VERSION ""

NS_ :

BS_:

BU_: HU

BO_ 285 VCU_HUDisp_2: 8 CGW
 SG_ VCU_MotActlSpdValid : 55|1@0+ (1,0) [0|1] "" TBox,HU

BO_ 400 iBCM_BCMSts: 8 CGW
 SG_ iBCM_AntitheftSts : 7|2@0+ (1,0) [0|3] "" TBox,HU
 SG_ iBCM_PwrMod : 5|2@0+ (1,0) [0|3] "" TBox,HU,PAS
 SG_ iBCM_HoodSts : 1|1@0+ (1,0) [0|1] "" HU
 SG_ iBCM_VhclDoorLckSts : 15|1@0+ (1,0) [0|1] "" TBox,HU
 SG_ iBCM_FL_DoorAjarSts : 14|1@0+ (1,0) [0|1] "" TBox,HU
 SG_ iBCM_FR_DoorAjarSts : 13|1@0+ (1,0) [0|1] "" TBox,HU
 SG_ iBCM_RL_DoorAjarSts : 12|1@0+ (1,0) [0|1] "" TBox,HU
 SG_ iBCM_RR_DoorAjarSts : 11|1@0+ (1,0) [0|1] "" TBox,HU
 SG_ iBCM_PBDLckSts : 23|1@0+ (1,0) [0|1] "" HU
 SG_ iBCM_PosnLiSts : 22|1@0+ (1,0) [0|1] "" HU
 SG_ iBCM_HiBeamSts : 21|1@0+ (1,0) [0|1] "" HU
 SG_ iBCM_LoBeamSts : 20|1@0+ (1,0) [0|1] "" HU
 SG_ iBCM_ReFogLiSts : 18|1@0+ (1,0) [0|1] "" HU
 SG_ iBCM_FrntFogLiSts : 17|1@0+ (1,0) [0|1] "" HU
 SG_ iBCM_TurnLiSts : 31|2@0+ (1,0) [0|3] "" TBox,HU
 SG_ iBCM_BrkLiSwch : 27|1@0+ (1,0) [0|1] "" HU
 SG_ iBCM_DrvrPresenceSgnl : 26|2@0+ (1,0) [0|3] "" HU
 SG_ iBCM_FolwMeHomeSts : 24|1@0+ (1,0) [0|1] "" HU
 SG_ iBCM_HomeTiDlySetg : 39|8@0+ (1,0) [0|60] "s" HU

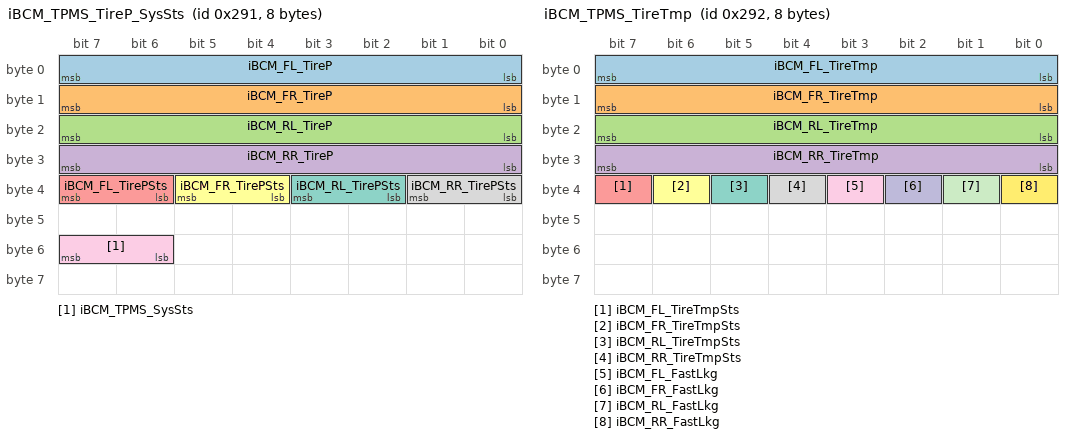
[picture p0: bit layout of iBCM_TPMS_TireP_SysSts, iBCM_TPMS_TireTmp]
BO_ 657 iBCM_TPMS_TireP_SysSts: 8 CGW
 SG_ iBCM_FL_TireP : 7|8@0+ (1.373,0) [0|348.742] "kpa" TBox,HU
 SG_ iBCM_FR_TireP : 15|8@0+ (1.373,0) [0|348.742] "kpa" TBox,HU
 SG_ iBCM_RL_TireP : 23|8@0+ (1.373,0) [0|348.742] "kpa" TBox,HU
 SG_ iBCM_RR_TireP : 31|8@0+ (1.373,0) [0|348.742] "kpa" TBox,HU
 SG_ iBCM_FL_TirePSts : 39|2@0+ (1,0) [0|3] "" TBox,HU
 SG_ iBCM_FR_TirePSts : 37|2@0+ (1,0) [0|3] "" TBox,HU
 SG_ iBCM_RL_TirePSts : 35|2@0+ (1,0) [0|3] "" TBox,HU
 SG_ iBCM_RR_TirePSts : 33|2@0+ (1,0) [0|3] "" TBox,HU
 SG_ iBCM_TPMS_SysSts : 55|2@0+ (1,0) [0|3] "" HU

BO_ 658 iBCM_TPMS_TireTmp: 8 CGW
 SG_ iBCM_FL_TireTmp : 7|8@0+ (1,-50) [-50|204] "℃" TBox,HU
 SG_ iBCM_FR_TireTmp : 15|8@0+ (1,-50) [-50|204] "℃" TBox,HU
 SG_ iBCM_RL_TireTmp : 23|8@0+ (1,-50) [-50|204] "℃" TBox,HU
 SG_ iBCM_RR_TireTmp : 31|8@0+ (1,-50) [-50|204] "℃" TBox,HU
 SG_ iBCM_FL_TireTmpSts : 39|1@0+ (1,0) [0|1] "" TBox,HU
 SG_ iBCM_FR_TireTmpSts : 38|1@0+ (1,0) [0|1] "" TBox,HU
 SG_ iBCM_RL_TireTmpSts : 37|1@0+ (1,0) [0|1] "" TBox,HU
 SG_ iBCM_RR_TireTmpSts : 36|1@0+ (1,0) [0|1] "" TBox,HU
 SG_ iBCM_FL_FastLkg : 35|1@0+ (1,0) [0|1] "" TBox,HU
 SG_ iBCM_FR_FastLkg : 34|1@0+ (1,0) [0|1] "" TBox,HU
 SG_ iBCM_RL_FastLkg : 33|1@0+ (1,0) [0|1] "" TBox,HU
 SG_ iBCM_RR_FastLkg : 32|1@0+ (1,0) [0|1] "" TBox,HU

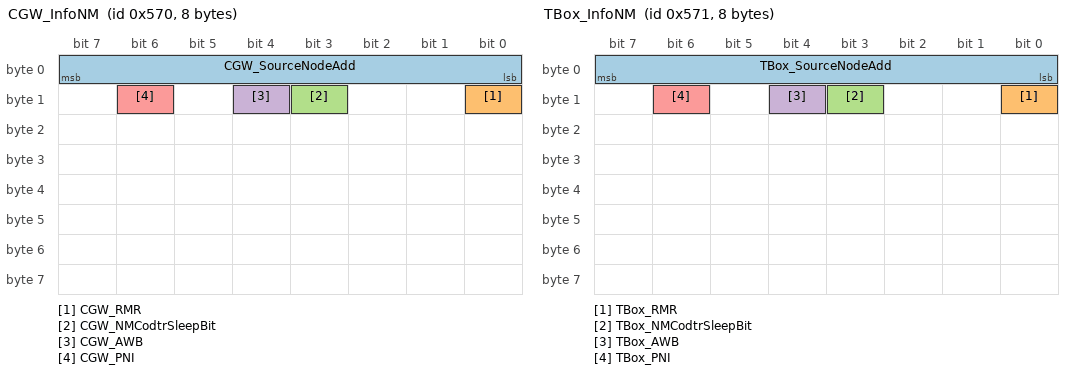
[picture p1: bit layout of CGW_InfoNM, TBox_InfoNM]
BO_ 1392 CGW_InfoNM: 8 CGW
 SG_ CGW_SourceNodeAdd : 7|8@0+ (1,0) [112|112] "" TBox,HU,AMP
 SG_ CGW_RMR : 8|1@0+ (1,0) [0|1] "" TBox,HU,AMP
 SG_ CGW_NMCodtrSleepBit : 11|1@0+ (1,0) [0|1] "" TBox,HU,AMP
 SG_ CGW_AWB : 12|1@0+ (1,0) [0|1] "" TBox,HU,AMP
 SG_ CGW_PNI : 14|1@0+ (1,0) [0|1] "" TBox,HU,AMP

BO_ 1393 TBox_InfoNM: 8 TBox
 SG_ TBox_SourceNodeAdd : 7|8@0+ (1,0) [113|113] "" HU,AMP,CGW
 SG_ TBox_RMR : 8|1@0+ (1,0) [0|1] "" HU,AMP,CGW
 SG_ TBox_NMCodtrSleepBit : 11|1@0+ (1,0) [0|1] "" HU,AMP,CGW
 SG_ TBox_AWB : 12|1@0+ (1,0) [0|1] "" HU,AMP,CGW
 SG_ TBox_PNI : 14|1@0+ (1,0) [0|1] "" HU,AMP,CGW

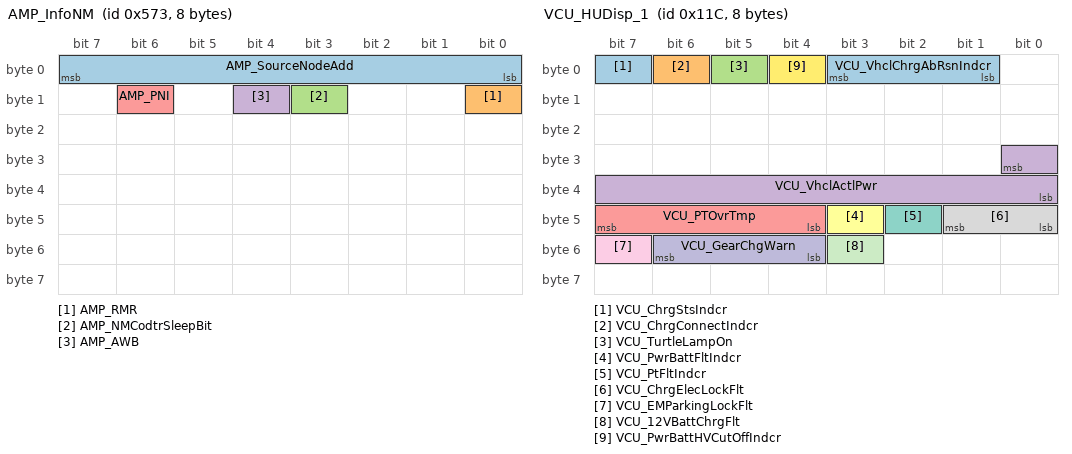
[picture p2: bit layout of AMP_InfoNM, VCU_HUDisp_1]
BO_ 1395 AMP_InfoNM: 8 AMP
 SG_ AMP_SourceNodeAdd : 7|8@0+ (1,0) [115|115] "" TBox,HU,CGW
 SG_ AMP_RMR : 8|1@0+ (1,0) [0|1] "" TBox,HU,CGW
 SG_ AMP_NMCodtrSleepBit : 11|1@0+ (1,0) [0|1] "" TBox,HU,CGW
 SG_ AMP_AWB : 12|1@0+ (1,0) [0|1] "" TBox,HU,CGW
 SG_ AMP_PNI : 14|1@0+ (1,0) [0|1] "" TBox,HU,CGW

BO_ 284 VCU_HUDisp_1: 8 CGW
 SG_ VCU_ChrgStsIndcr : 7|1@0+ (1,0) [0|1] "" TBox,HU,AMP
 SG_ VCU_ChrgConnectIndcr : 6|1@0+ (1,0) [0|1] "" TBox,HU
 SG_ VCU_TurtleLampOn : 5|1@0+ (1,0) [0|1] "" HU
 SG_ VCU_VhclActlPwr : 24|9@0+ (1,-200) [-200|300] "kw" HU
 SG_ VCU_PTOvrTmp : 47|4@0+ (1,0) [0|15] "" HU
 SG_ VCU_PwrBattFltIndcr : 43|1@0+ (1,0) [0|1] "" HU
 SG_ VCU_PtFltIndcr : 42|1@0+ (1,0) [0|1] "" HU
 SG_ VCU_ChrgElecLockFlt : 41|2@0+ (1,0) [0|3] "" HU
 SG_ VCU_EMParkingLockFlt : 55|1@0+ (1,0) [0|1] "" HU
 SG_ VCU_GearChgWarn : 54|3@0+ (1,0) [0|7] "" HU
 SG_ VCU_12VBattChrgFlt : 51|1@0+ (1,0) [0|1] "" HU
 SG_ VCU_PwrBattHVCutOffIndcr : 4|1@0+ (1,0) [0|1] "" HU
 SG_ VCU_VhclChrgAbRsnIndcr : 3|3@0+ (1,0) [0|7] "" HU

BO_ 369 CGW_ChassisToInfo: 8 CGW
 SG_ ESP_VhclSpd : 7|13@0+ (0.05625,0) [0|300] "km/h" TBox,HU,AMP,PAS
 SG_ ESP_VhclSpd_Vld : 10|1@0+ (1,0) [0|1] "" TBox,HU,AMP,PAS
 SG_ ESP_OFFLamp : 9|1@0+ (1,0) [0|1] "" HU
 SG_ ESP_Err : 8|1@0+ (1,0) [0|1] "" HU
 SG_ ESP_ABS_Err : 23|1@0+ (1,0) [0|1] "" HU
 SG_ ESP_EBD_Err : 22|1@0+ (1,0) [0|1] "" HU
 SG_ ESP_HMI_WarnOn : 21|1@0+ (1,0) [0|1] "" HU
 SG_ ESP_Actv : 20|1@0+ (1,0) [0|1] "" HU
 SG_ ESP_EPB_WarnMsg : 19|4@0+ (1,0) [0|15] "" HU
 SG_ ESP_EPB_FltLamp : 31|2@0+ (1,0) [0|3] "" TBox,HU,PAS
 SG_ ESP_EPB_FctLamp : 29|2@0+ (1,0) [0|3] "" HU
 SG_ ESP_AVH_Avl : 24|1@0+ (1,0) [0|1] "" HU
 SG_ ESP_AVH_Actv : 39|1@0+ (1,0) [0|1] "" HU
 SG_ ESP_HDC_Avl : 38|1@0+ (1,0) [0|1] "" HU
 SG_ ESP_HDC_Sts : 37|2@0+ (1,0) [0|3] "" HU
 SG_ iB_HU_WarnOn : 32|1@0+ (1,0) [0|1] "" HU
 SG_ EPS_Sts : 47|2@0+ (1,0) [0|3] "" HU

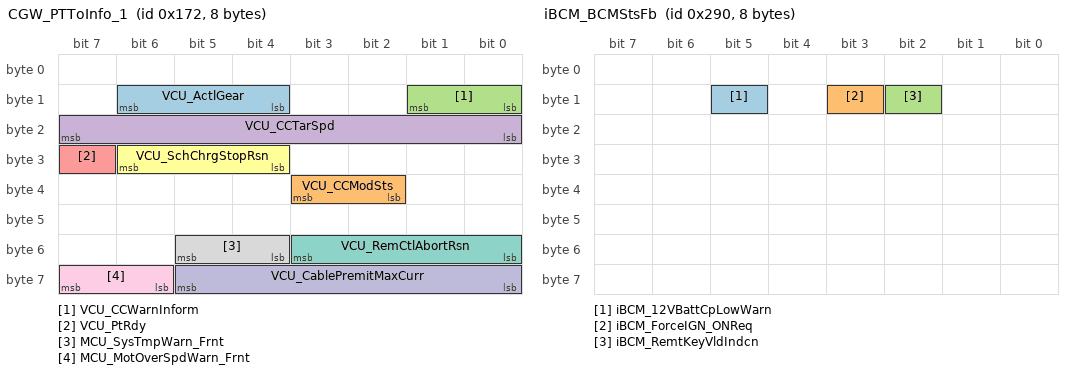
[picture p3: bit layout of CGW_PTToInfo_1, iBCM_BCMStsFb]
BO_ 370 CGW_PTToInfo_1: 8 CGW
 SG_ VCU_ActlGear : 14|3@0+ (1,0) [0|7] "" TBox,HU,AMP,PAS
 SG_ VCU_CCModSts : 35|2@0+ (1,0) [0|3] "" HU
 SG_ VCU_CCWarnInform : 9|2@0+ (1,0) [0|3] "" HU
 SG_ VCU_CCTarSpd : 23|8@0+ (1,0) [0|150] "km/h" HU
 SG_ VCU_PtRdy : 31|1@0+ (1,0) [0|1] "" TBox,HU,AMP,PAS
 SG_ VCU_SchChrgStopRsn : 30|3@0+ (1,0) [0|7] "" TBox,HU
 SG_ VCU_RemCtlAbortRsn : 51|4@0+ (1,0) [0|15] "" HU
 SG_ MCU_SysTmpWarn_Frnt : 53|2@0+ (1,0) [0|3] "" HU
 SG_ MCU_MotOverSpdWarn_Frnt : 63|2@0+ (1,0) [0|3] "" HU
 SG_ VCU_CablePremitMaxCurr : 61|6@0+ (1,0) [8|32] "A" HU

BO_ 656 iBCM_BCMStsFb: 8 CGW
 SG_ iBCM_12VBattCpLowWarn : 13|1@0+ (1,0) [0|1] "" HU
 SG_ iBCM_ForceIGN_ONReq : 11|1@0+ (1,0) [0|1] "" HU
 SG_ iBCM_RemtKeyVldIndcn : 10|1@0+ (1,0) [0|1] "" HU

BO_ 880 TBox_Order: 8 TBox
 SG_ TBox_CurChrgnMod : 6|2@0+ (1,0) [0|3] "" HU,CGW
 SG_ TBox_E_CallSts : 47|2@0+ (1,0) [0|3] "" HU,CGW

CM_ SG_ 1395 AMP_SourceNodeAdd "Source Node Address
原节点地址";
CM_ SG_ 1395 AMP_RMR "Repeat message request
重复报文请求";
CM_ SG_ 1395 AMP_NMCodtrSleepBit "NM Coordinator Sleep Bit
网络管理协调睡眠指示位";
CM_ SG_ 1395 AMP_AWB "Active wakeup bit
主动唤醒指示位";
CM_ SG_ 1395 AMP_PNI "Partial netwark information bit 
局部网络指示位";
CM_ SG_ 880 TBox_CurChrgnMod "Current Charging Mode
当前充电模式信号";
CM_ SG_ 880 TBox_E_CallSts "TBox_EmergencyCallStatus
一键呼叫通话状态";
CM_ SG_ 1393 TBox_SourceNodeAdd "Source Node Address
原节点地址";
CM_ SG_ 1393 TBox_RMR "Repeat message request
重复报文请求";
CM_ SG_ 1393 TBox_NMCodtrSleepBit "NM Coordinator Sleep Bit
网络管理协调睡眠指示位";
CM_ SG_ 1393 TBox_AWB "Active wakeup bit
主动唤醒指示位";
CM_ SG_ 1393 TBox_PNI "Partial netwark information bit 
局部网络指示位";
CM_ SG_ 1392 CGW_SourceNodeAdd "Source Node Address
原节点地址";
CM_ SG_ 1392 CGW_RMR "Repeat message request
重复报文请求";
CM_ SG_ 1392 CGW_NMCodtrSleepBit "NM Coordinator Sleep Bit
网络管理协调睡眠指示位";
CM_ SG_ 1392 CGW_AWB "Active wakeup bit
主动唤醒指示位";
CM_ SG_ 1392 CGW_PNI "Partial netwark information bit 
局部网络指示位";
CM_ SG_ 284 VCU_ChrgStsIndcr "Charge status indicator
充电状态指示";
CM_ SG_ 284 VCU_ChrgConnectIndcr "Charge connect indicator
充电链接指示";
CM_ SG_ 284 VCU_TurtleLampOn "TurtleLampOn
（乌龟灯）驱动功率受限指示灯";
CM_ SG_ 284 VCU_VhclActlPwr "Vehicle actual power
车辆实际功率";
CM_ SG_ 284 VCU_PTOvrTmp "Powertrain over temperature
动力系统过温";
CM_ SG_ 284 VCU_PwrBattFltIndcr "Power battery fault indicator
动力电池故障指示";
CM_ SG_ 284 VCU_PtFltIndcr "Powertrain fault indicator
动力系统故障指示";
CM_ SG_ 284 VCU_ChrgElecLockFlt "Charging electrical lock fault
充电电子锁故障";
CM_ SG_ 284 VCU_EMParkingLockFlt "EM parking lock fault
电机驻车锁故障";
CM_ SG_ 284 VCU_GearChgWarn "Gear Change Warning
换档条件不满足";
CM_ SG_ 284 VCU_12VBattChrgFlt "Battery(12V) Charging Fault
12V蓄电池充电故障指示";
CM_ SG_ 284 VCU_PwrBattHVCutOffIndcr "Power Battery High Voltage Cut Off  Indicator
动力电池高压切断指示";
CM_ SG_ 284 VCU_VhclChrgAbRsnIndcr "Vehicle Charge Abnormal  Reason Indicator
车辆充电异常原因指示";
CM_ SG_ 285 VCU_MotActlSpdValid "Motor Actual speed validity 
电机实际转速有效";
CM_ SG_ 370 VCU_ActlGear "Actual gear";
CM_ SG_ 370 VCU_CCModSts "Cruise control mode status
巡航控制模式状态";
CM_ SG_ 370 VCU_CCWarnInform "Cruise control warning information
巡航控制报警信息";
CM_ SG_ 370 VCU_CCTarSpd "Cruise control target speed
巡航目标车速";
CM_ SG_ 370 VCU_PtRdy "Powertrain have ready
动力系统准备就绪";
CM_ SG_ 370 VCU_SchChrgStopRsn "Schedule charging stop reason
预约充电停止充电的原因";
CM_ SG_ 370 VCU_RemCtlAbortRsn "Remote control abort reason
远程控制失败的原因";
CM_ SG_ 370 MCU_SysTmpWarn_Frnt "Systerm temperature waring
电机系统温度报警";
CM_ SG_ 370 MCU_MotOverSpdWarn_Frnt "Motor over speed warnig
电机超速报警";
CM_ SG_ 370 VCU_CablePremitMaxCurr "AC Charging cable premit max current
交流充电线缆允许的最大电流";
CM_ SG_ 369 ESP_VhclSpd "Vehicle speed out";
CM_ SG_ 369 ESP_VhclSpd_Vld "Vehicle speed out status";
CM_ SG_ 369 ESP_OFFLamp "ESP is diabled by PATA(PATALamp)
（ESP_OFF Switch)";
CM_ SG_ 369 ESP_Err "ESP_Fault: VDC/TCS is switched off due to detected failure";
CM_ SG_ 369 ESP_ABS_Err "ABS_Fault: ESP system has detected a failure which does not allow a reliable ABS regulation and is therefore switched off";
CM_ SG_ 369 ESP_EBD_Err "EBD_Fault: ESP system has detected a heavy fault, which does not even allow a reliable electronic brake distribution and is therefore completely shut down";
CM_ SG_ 369 ESP_HMI_WarnOn "Warning lamp of ESPhev
(iBooster fault indicator)";
CM_ SG_ 369 ESP_Actv "Info lamp  Indication that VDC/TCS(brake torque control) system currently performs a brake intervention";
CM_ SG_ 369 ESP_EPB_WarnMsg "Additional warning message to inform the driver how to do the next step.";
CM_ SG_ 369 ESP_EPB_FltLamp "EPB_FailureLamp";
CM_ SG_ 369 ESP_EPB_FctLamp "EPB_FunctionLamp";
CM_ SG_ 369 ESP_AVH_Avl "HMI Responsible,CAN get degrateAVH statement from DSW(Didgnostic Software) and send out";
CM_ SG_ 369 ESP_AVH_Actv "Indicates AVH in active or not ";
CM_ SG_ 369 ESP_HDC_Avl "HMI Responsible,CAN get degrate HDC statement from DSW and send out";
CM_ SG_ 369 ESP_HDC_Sts "HDC Status(Off/On, not active braking/On, active braking)
HDC state is used for light the dashboard lamp for Off, Standby, active: 
Off, the lamp is Off;
Standby, the lamp is On;
Active,the lamp is blinking.";
CM_ SG_ 369 iB_HU_WarnOn "Warning lamp of iBooster";
CM_ SG_ 369 EPS_Sts "EPS Status
EPS系统状态信号";
CM_ SG_ 657 iBCM_FL_TireP "TireLeftFrontPressure
左前轮胎压压力";
CM_ SG_ 657 iBCM_FR_TireP "TireRightFrontPressure
右前轮胎压压力";
CM_ SG_ 657 iBCM_RL_TireP "TireLeftRearPressure
左后轮胎压压力";
CM_ SG_ 657 iBCM_RR_TireP "TireRightRearPressure
右后轮胎压压力";
CM_ SG_ 657 iBCM_FL_TirePSts "TireLeftFrontPressureStatus
左前轮胎压状态";
CM_ SG_ 657 iBCM_FR_TirePSts "TireRightFrontPressureStatus
右前轮胎压状态";
CM_ SG_ 657 iBCM_RL_TirePSts "TireLeftRearPressureStatus
左后轮胎压状态";
CM_ SG_ 657 iBCM_RR_TirePSts "TireRightRearPressureStatus
右后轮胎压状态";
CM_ SG_ 657 iBCM_TPMS_SysSts "TPMSSystemStatus
TPMS系统状态";
CM_ SG_ 658 iBCM_FL_TireTmp "TireLeftFrontTemperature
左前轮胎温";
CM_ SG_ 658 iBCM_FR_TireTmp "TireRightFrontTemperature
右前轮胎温";
CM_ SG_ 658 iBCM_RL_TireTmp "TireLeftRearTemperature
左后轮胎温";
CM_ SG_ 658 iBCM_RR_TireTmp "TireRightRearTemperature
右后轮胎温";
CM_ SG_ 658 iBCM_FL_TireTmpSts "TireLeftFrontTemperatureStatus
左前轮轮胎温状态";
CM_ SG_ 658 iBCM_FR_TireTmpSts "TireRightFrontTemperatureStatus
右前轮轮胎温状态";
CM_ SG_ 658 iBCM_RL_TireTmpSts "TireLeftRearTemperatureStatus
左后轮轮胎温状态";
CM_ SG_ 658 iBCM_RR_TireTmpSts "TireRightRearTemperatureStatus
右后轮轮胎温状态";
CM_ SG_ 658 iBCM_FL_FastLkg "Tire Front Left FastLeakage
左前轮快速漏气(预留)";
CM_ SG_ 658 iBCM_FR_FastLkg "Tire Front Right FastLeakage
右前轮快速漏气(预留)";
CM_ SG_ 658 iBCM_RL_FastLkg "Tire Rear Left FastLeakage
左后轮快速漏气(预留)";
CM_ SG_ 658 iBCM_RR_FastLkg "Tire Rear Right Fast Leakage
右后轮快速漏气(预留)";
CM_ SG_ 656 iBCM_12VBattCpLowWarn "Battery(12V) Capacity Low Warning
12V电池低电量信号";
CM_ SG_ 656 iBCM_ForceIGN_ONReq "Force IGN ON Request
（座椅传感器失效时）请求用户确认是否强制IGN ON";
CM_ SG_ 656 iBCM_RemtKeyVldIndcn "Valid Indication of the Remote Key 
遥控钥匙有效指示位";
CM_ SG_ 400 iBCM_AntitheftSts "Vehicle Antitheft Status
防盗报警状态";
CM_ SG_ 400 iBCM_PwrMod "Power Mode
系统电源";
CM_ SG_ 400 iBCM_HoodSts "Hood Status
前舱盖开关";
CM_ SG_ 400 iBCM_VhclDoorLckSts "Vehicle Door Lock Status
整车门锁状态";
CM_ SG_ 400 iBCM_FL_DoorAjarSts "Driver Door Ajar Status
驾驶侧门开关状态";
CM_ SG_ 400 iBCM_FR_DoorAjarSts "Passenger Door Ajar Status
副驾驶侧门开关状态";
CM_ SG_ 400 iBCM_RL_DoorAjarSts "Rear Left Door Ajar Status
左后门开关状态";
CM_ SG_ 400 iBCM_RR_DoorAjarSts "Rear Right Door Ajar Status
右后门开关状态";
CM_ SG_ 400 iBCM_PBDLckSts "PBD Lock Status
电动背门锁状态";
CM_ SG_ 400 iBCM_PosnLiSts "Position Light Status
位置灯状态";
CM_ SG_ 400 iBCM_HiBeamSts "High Beam Status
远光灯状态";
CM_ SG_ 400 iBCM_LoBeamSts "Low Beam status
近光灯状态";
CM_ SG_ 400 iBCM_ReFogLiSts "Rear Fog Lamp Status 
后雾灯状态";
CM_ SG_ 400 iBCM_FrntFogLiSts "Front Fog Lamp Status 
前雾灯状态";
CM_ SG_ 400 iBCM_TurnLiSts "Turn Lamp Status and Hazard Warning Lamp Status
 转向灯/危险警告状态";
CM_ SG_ 400 iBCM_BrkLiSwch "Brake Light Switch
制动灯开关信号";
CM_ SG_ 400 iBCM_DrvrPresenceSgnl "Driver Presence Signal
座椅传感器信号";
CM_ SG_ 400 iBCM_FolwMeHomeSts "Follow Me Home Function Status
伴我回家功能（启闭）状态";
CM_ SG_ 400 iBCM_HomeTiDlySetg "The setting of Follow Me Home TimeDely  in iBCM  Memory
iBCM内伴我回家灯延迟时间设定";

BA_DEF_ BO_  "NmMessage" ENUM "No","Yes";
BA_DEF_ BO_  "GenMsgSendType" ENUM  "Cycle","NoSendType","IfActive";
BA_DEF_ BO_  "GenMsgCycleTime" INT 0 0;
BA_DEF_ SG_  "GenSigSendType" ENUM  "Cycle","OnChange","OnWrite","IfActive","OnChangeWithRepetition","OnWriteWithRepetition","IfActiveWithRepetition";
BA_DEF_ SG_  "GenSigStartValue" INT 0 0;
BA_DEF_ BO_  "GenMsgCycleTimeFast" INT 0 0;
BA_DEF_ BO_  "GenMsgNrOfRepetition" INT 0 0;
BA_DEF_ BO_  "VFrameFormat" ENUM  "StandardCAN","ExtendedCAN","reserved","reserved","reserved","reserved","reserved","reserved","reserved","reserved","reserved","reserved","reserved","reserved","StandardCAN_FD","ExtendedCAN_FD";

BA_DEF_DEF_  "NmMessage" "No";
BA_DEF_DEF_  "GenMsgSendType" "Cycle";
BA_DEF_DEF_  "GenMsgCycleTime" 0;
BA_DEF_DEF_  "GenSigSendType" "Cycle";
BA_DEF_DEF_  "GenSigStartValue" 0;
BA_DEF_DEF_  "GenMsgCycleTimeFast" 0;
BA_DEF_DEF_  "GenMsgNrOfRepetition" 0;
BA_DEF_DEF_  "VFrameFormat" "StandardCAN";
BA_ "GenMsgCycleTime" BO_ 400 100;
BA_ "GenMsgCycleTime" BO_ 657 200;
BA_ "GenSigStartValue" SG_ 657 iBCM_FL_TireP 255;
BA_ "GenSigStartValue" SG_ 657 iBCM_FR_TireP 255;
BA_ "GenSigStartValue" SG_ 657 iBCM_RL_TireP 255;
BA_ "GenSigStartValue" SG_ 657 iBCM_RR_TireP 255;
BA_ "GenMsgCycleTime" BO_ 658 200;
BA_ "GenSigStartValue" SG_ 658 iBCM_FL_TireTmp 255;
BA_ "GenSigStartValue" SG_ 658 iBCM_FR_TireTmp 255;
BA_ "GenSigStartValue" SG_ 658 iBCM_RL_TireTmp 255;
BA_ "GenSigStartValue" SG_ 658 iBCM_RR_TireTmp 255;
BA_ "NmMessage" BO_ 1392 1;
BA_ "GenMsgCycleTime" BO_ 1392 500;
BA_ "GenMsgCycleTimeFast" BO_ 1392 10;
BA_ "GenMsgNrOfRepetition" BO_ 1392 5;
BA_ "GenSigSendType" SG_ 1392 CGW_SourceNodeAdd 6;
BA_ "GenSigStartValue" SG_ 1392 CGW_SourceNodeAdd 112;
BA_ "GenSigSendType" SG_ 1392 CGW_RMR 6;
BA_ "GenSigSendType" SG_ 1392 CGW_NMCodtrSleepBit 6;
BA_ "GenSigSendType" SG_ 1392 CGW_AWB 6;
BA_ "GenSigSendType" SG_ 1392 CGW_PNI 6;
BA_ "NmMessage" BO_ 1393 1;
BA_ "GenMsgCycleTime" BO_ 1393 500;
BA_ "GenMsgCycleTimeFast" BO_ 1393 10;
BA_ "GenMsgNrOfRepetition" BO_ 1393 5;
BA_ "GenSigSendType" SG_ 1393 TBox_SourceNodeAdd 6;
BA_ "GenSigStartValue" SG_ 1393 TBox_SourceNodeAdd 113;
BA_ "GenSigSendType" SG_ 1393 TBox_RMR 6;
BA_ "GenSigSendType" SG_ 1393 TBox_NMCodtrSleepBit 6;
BA_ "GenSigSendType" SG_ 1393 TBox_AWB 6;
BA_ "GenSigSendType" SG_ 1393 TBox_PNI 6;
BA_ "NmMessage" BO_ 1395 1;
BA_ "GenMsgCycleTime" BO_ 1395 500;
BA_ "GenMsgCycleTimeFast" BO_ 1395 10;
BA_ "GenMsgNrOfRepetition" BO_ 1395 5;
BA_ "GenSigSendType" SG_ 1395 AMP_SourceNodeAdd 6;
BA_ "GenSigStartValue" SG_ 1395 AMP_SourceNodeAdd 115;
BA_ "GenSigSendType" SG_ 1395 AMP_RMR 6;
BA_ "GenSigSendType" SG_ 1395 AMP_NMCodtrSleepBit 6;
BA_ "GenSigSendType" SG_ 1395 AMP_AWB 6;
BA_ "GenSigSendType" SG_ 1395 AMP_PNI 6;
BA_ "GenMsgCycleTime" BO_ 284 100;
BA_ "GenSigStartValue" SG_ 284 VCU_VhclActlPwr 200;
BA_ "GenMsgCycleTime" BO_ 369 20;
BA_ "GenSigStartValue" SG_ 369 ESP_Err 1;
BA_ "GenSigStartValue" SG_ 369 ESP_ABS_Err 1;
BA_ "GenSigStartValue" SG_ 369 ESP_EBD_Err 1;
BA_ "GenMsgCycleTime" BO_ 370 50;
BA_ "GenSigStartValue" SG_ 370 VCU_CablePremitMaxCurr 8;
BA_ "GenMsgCycleTime" BO_ 656 100;
BA_ "GenMsgCycleTime" BO_ 880 50;
VAL_ 1395 AMP_RMR 1 "Rpt Msg state req" 0 "Rpt Msg state not req" ;
VAL_ 1395 AMP_NMCodtrSleepBit 1 "Synch Shutdwn Req by codtr" 0 "Synch Shutdwn NotReq by codtr" ;
VAL_ 1395 AMP_AWB 1 "Active wakeup" 0 "Passive wakeup" ;
VAL_ 1395 AMP_PNI 1 "Contain PNI" 0 "Contain no PNI" ;
VAL_ 880 TBox_CurChrgnMod 3 "Reserved" 2 "Reserved" 1 "Remote Charging Mode" 0 "Normal Charging Mode" ;
VAL_ 880 TBox_E_CallSts 3 "Hang up" 2 "Call connection" 1 "Dialing" 0 "No request" ;
VAL_ 1393 TBox_RMR 1 "Rpt Msg state req" 0 "Rpt Msg state not req" ;
VAL_ 1393 TBox_NMCodtrSleepBit 1 "Synch Shutdwn Req by codtr" 0 "Synch Shutdwn NotReq by codtr" ;
VAL_ 1393 TBox_AWB 1 "Active wakeup" 0 "Passive wakeup" ;
VAL_ 1393 TBox_PNI 1 "Contain PNI" 0 "Contain no PNI" ;
VAL_ 1392 CGW_RMR 1 "Rpt Msg state req" 0 "Rpt Msg state not req" ;
VAL_ 1392 CGW_NMCodtrSleepBit 1 "Synch Shutdwn Req by codtr" 0 "Synch Shutdwn NotReq by codtr" ;
VAL_ 1392 CGW_AWB 1 "Active wakeup" 0 "Passive wakeup" ;
VAL_ 1392 CGW_PNI 1 "Contain PNI" 0 "Contain no PNI" ;
VAL_ 284 VCU_ChrgStsIndcr 1 "True" 0 "False" ;
VAL_ 284 VCU_ChrgConnectIndcr 1 "True" 0 "False" ;
VAL_ 284 VCU_TurtleLampOn 1 "Lamp on" 0 "Lamp off" ;
VAL_ 284 VCU_VhclActlPwr 511 "Invalid" 510 "Invalid" 509 "Invalid" 508 "Invalid" 507 "Invalid" 506 "Invalid" 505 "Invalid" 504 "Invalid" 503 "Invalid" 502 "Invalid" 501 "Invalid" ;
VAL_ 284 VCU_PTOvrTmp 15 "Reserved" 14 "Reserved" 13 "Reserved" 12 "Reserved" 11 "Reserved" 10 "Reserved" 9 "Reserved" 8 "Reserved" 7 "Reserved" 6 "Reserved" 5 "Reserved" 4 "PTCoolant over tmp" 3 "Both Front and Rear Motor system over tmp" 2 "Rear Motor system over tmp" 1 "Front Motor system over tmp" 0 "Normal" ;
VAL_ 284 VCU_PwrBattFltIndcr 1 "True" 0 "False" ;
VAL_ 284 VCU_PtFltIndcr 1 "True" 0 "False" ;
VAL_ 284 VCU_ChrgElecLockFlt 3 "Reserved" 2 "Electrincal Lock can't Opened" 1 "Electrincal Lock can't Locked" 0 "No fault" ;
VAL_ 284 VCU_EMParkingLockFlt 1 "Fault" 0 "No fault" ;
VAL_ 284 VCU_GearChgWarn 7 "Reserved" 6 "Reserved" 5 "GSM Fault" 4 "PT fault can't change gear" 3 "Close door to shift none P" 2 "Press BrkPed to shift none P" 1 "Vehicle speed too high" 0 "No warning" ;
VAL_ 284 VCU_12VBattChrgFlt 1 "Error" 0 "No Error" ;
VAL_ 284 VCU_PwrBattHVCutOffIndcr 1 "Cut Off" 0 "No Cut Off" ;
VAL_ 284 VCU_VhclChrgAbRsnIndcr 7 "Reserved" 6 "Reserved" 5 "Reserved" 4 "Reserved" 3 "Reserved" 2 "Chrg Timeout, Please Check" 1 "Vhcl Not On P,Cannot Chrg" 0 "Normal" ;
VAL_ 285 VCU_MotActlSpdValid 1 "Validity" 0 "Invalidity" ;
VAL_ 370 VCU_ActlGear 7 "Reserved" 6 "Reserved" 5 "Reserved" 4 "Reserved" 3 "D" 2 "N" 1 "R" 0 "P" ;
VAL_ 370 VCU_CCModSts 3 "Cancel" 2 "Active" 1 "Standby" 0 "Off" ;
VAL_ 370 VCU_CCWarnInform 3 "Reserved" 2 "CC systerm fault" 1 "Condition not fulfill" 0 "No error" ;
VAL_ 370 VCU_CCTarSpd 255 "Invalid" 254 "Invalid" 253 "Invalid" 252 "Invalid" 251 "Invalid" 250 "Invalid" 249 "Invalid" 248 "Invalid" 247 "Invalid" 246 "Invalid" 245 "Invalid" 244 "Invalid" 243 "Invalid" 242 "Invalid" 241 "Invalid" 240 "Invalid" 239 "Invalid" 238 "Invalid" 237 "Invalid" 236 "Invalid" 235 "Invalid" 234 "Invalid" 233 "Invalid" 232 "Invalid" 231 "Invalid" 230 "Invalid" 229 "Invalid" 228 "Invalid" 227 "Invalid" 226 "Invalid" 225 "Invalid" 224 "Invalid" 223 "Invalid" 222 "Invalid" 221 "Invalid" 220 "Invalid" 219 "Invalid" 218 "Invalid" 217 "Invalid" 216 "Invalid" 215 "Invalid" 214 "Invalid" 213 "Invalid" 212 "Invalid" 211 "Invalid" 210 "Invalid" 209 "Invalid" 208 "Invalid" 207 "Invalid" 206 "Invalid" 205 "Invalid" 204 "Invalid" 203 "Invalid" 202 "Invalid" 201 "Invalid" 200 "Invalid" 199 "Invalid" 198 "Invalid" 197 "Invalid" 196 "Invalid" 195 "Invalid" 194 "Invalid" 193 "Invalid" 192 "Invalid" 191 "Invalid" 190 "Invalid" 189 "Invalid" 188 "Invalid" 187 "Invalid" 186 "Invalid" 185 "Invalid" 184 "Invalid" 183 "Invalid" 182 "Invalid" 181 "Invalid" 180 "Invalid" 179 "Invalid" 178 "Invalid" 177 "Invalid" 176 "Invalid" 175 "Invalid" 174 "Invalid" 173 "Invalid" 172 "Invalid" 171 "Invalid" 170 "Invalid" 169 "Invalid" 168 "Invalid" 167 "Invalid" 166 "Invalid" 165 "Invalid" 164 "Invalid" 163 "Invalid" 162 "Invalid" 161 "Invalid" 160 "Invalid" 159 "Invalid" 158 "Invalid" 157 "Invalid" 156 "Invalid" 155 "Invalid" 154 "Invalid" 153 "Invalid" 152 "Invalid" 151 "Invalid" ;
VAL_ 370 VCU_PtRdy 1 "True" 0 "False" ;
VAL_ 370 VCU_SchChrgStopRsn 7 "Reserved" 6 "Crash happened" 5 "Charging gun not plug in" 4 "220V not connect(CC but no CP)" 3 "Normal stop" 2 "PT system fault stop" 1 "Charging full stop" 0 "Default" ;
VAL_ 370 VCU_RemCtlAbortRsn 15 "Reserved" 14 "Reserved" 13 "Reserved" 12 "Reserved" 11 "Reserved" 10 "Reserved" 9 "Reserved" 8 "SOC low" 7 "Permit Max time timeout" 6 "Driver intervene Accr Ped" 5 "Driver intervene Brake Ped" 4 "Driver intervene Gear" 3 "Plug in charging gun" 2 "PT system fault" 1 "None P" 0 "Default" ;
VAL_ 370 MCU_SysTmpWarn_Frnt 3 "Coolant over tmp dreating" 2 "Motore over tmp dreating" 1 "MCU over tmp dreating" 0 "Normal" ;
VAL_ 370 MCU_MotOverSpdWarn_Frnt 3 "Reserved" 2 "Fault" 1 "Derating" 0 "Normal" ;
VAL_ 370 VCU_CablePremitMaxCurr 63 "Invalid" 62 "Invalid" 61 "Invalid" 60 "Invalid" 59 "Invalid" 58 "Invalid" 57 "Invalid" 56 "Invalid" 55 "Invalid" 54 "Invalid" 53 "Invalid" 52 "Invalid" 51 "Invalid" 50 "Invalid" 49 "Invalid" 48 "Invalid" 47 "Invalid" 46 "Invalid" 45 "Invalid" 44 "Invalid" 43 "Invalid" 42 "Invalid" 41 "Invalid" 40 "Invalid" 39 "Invalid" 38 "Invalid" 37 "Invalid" 36 "Invalid" 35 "Invalid" 34 "Invalid" 33 "Invalid" ;
VAL_ 369 ESP_VhclSpd 8191 "Invalid" ;
VAL_ 369 ESP_VhclSpd_Vld 1 "Validity" 0 "Invalidity" ;
VAL_ 369 ESP_OFFLamp 1 "Lamp On" 0 "Lamp Off" ;
VAL_ 369 ESP_Err 1 "Error" 0 "No error" ;
VAL_ 369 ESP_ABS_Err 1 "Error" 0 "No error" ;
VAL_ 369 ESP_EBD_Err 1 "Error" 0 "No error" ;
VAL_ 369 ESP_HMI_WarnOn 1 "Warning lamp requested" 0 "No request to the warning lamp" ;
VAL_ 369 ESP_Actv 1 "Active" 0 "Not active" ;
VAL_ 369 ESP_EPB_WarnMsg 15 "Reserved" 14 "Reserved" 13 "Reserved" 12 "Reserved" 11 "Reserved" 10 "Reserved" 9 "Roller Bench Mode" 8 "Contact Service to check EPB" 7 "ClampForceNotEnough ?" 6 "GradientTooHigh ?" 5 "MaintenanceModeActive" 4 "DynamicBrakingActive ?" 3 "PressBrakePedal ?" 2 "OpenEPBBySwitch ?" 1 "FastenSeatBelt ?" 0 "Off" ;
VAL_ 369 ESP_EPB_FltLamp 3 "Reserved" 2 "EPB failure lamp blinking" 1 "EPB failure lamp On" 0 "EPB failure lamp Off" ;
VAL_ 369 ESP_EPB_FctLamp 3 "Reserved" 2 "EPB function lamp blinking" 1 "EPB function lamp On" 0 "EPB function lamp Off" ;
VAL_ 369 ESP_AVH_Avl 1 "Available" 0 "Not available" ;
VAL_ 369 ESP_AVH_Actv 1 "Active" 0 "Not active" ;
VAL_ 369 ESP_HDC_Avl 1 "Available" 0 "Not available" ;
VAL_ 369 ESP_HDC_Sts 3 "Reserved" 2 "On active braking" 1 "On not active braking" 0 "OFF" ;
VAL_ 369 iB_HU_WarnOn 1 "iB Lamp Active" 0 "No iB Lamp" ;
VAL_ 369 EPS_Sts 3 "Reserved" 2 "Intermittent Error Detected" 1 "Permanent Error Detected" 0 "No Fault" ;
VAL_ 657 iBCM_FL_TireP 255 "Invalid" ;
VAL_ 657 iBCM_FR_TireP 255 "Invalid" ;
VAL_ 657 iBCM_RL_TireP 255 "Invalid" ;
VAL_ 657 iBCM_RR_TireP 255 "Invalid" ;
VAL_ 657 iBCM_FL_TirePSts 3 "Reserved" 2 "Under-pressure" 1 "Over-pressure" 0 "Normal" ;
VAL_ 657 iBCM_FR_TirePSts 3 "Reserved" 2 "Under-pressure" 1 "Over-pressure" 0 "Normal" ;
VAL_ 657 iBCM_RL_TirePSts 3 "Reserved" 2 "Under-pressure" 1 "Over-pressure" 0 "Normal" ;
VAL_ 657 iBCM_RR_TirePSts 3 "Reserved" 2 "Under-pressure" 1 "Over-pressure" 0 "Normal" ;
VAL_ 657 iBCM_TPMS_SysSts 3 "Reserved" 2 "Reserved" 1 "System is abnormal" 0 "System is ok" ;
VAL_ 658 iBCM_FL_TireTmp 255 "Invalid" ;
VAL_ 658 iBCM_FR_TireTmp 255 "Invalid" ;
VAL_ 658 iBCM_RL_TireTmp 255 "Invalid" ;
VAL_ 658 iBCM_RR_TireTmp 255 "Invalid" ;
VAL_ 658 iBCM_FL_TireTmpSts 1 "Over-temp" 0 "Normal" ;
VAL_ 658 iBCM_FR_TireTmpSts 1 "Over-temp" 0 "Normal" ;
VAL_ 658 iBCM_RL_TireTmpSts 1 "Over-temp" 0 "Normal" ;
VAL_ 658 iBCM_RR_TireTmpSts 1 "Over-temp" 0 "Normal" ;
VAL_ 658 iBCM_FL_FastLkg 1 "Fast Leakage" 0 "Not Fast Leakage" ;
VAL_ 658 iBCM_FR_FastLkg 1 "Fast Leakage" 0 "Not Fast Leakage" ;
VAL_ 658 iBCM_RL_FastLkg 1 "Fast Leakage" 0 "Not Fast Leakage" ;
VAL_ 658 iBCM_RR_FastLkg 1 "Fast Leakage" 0 "Not Fast Leakage" ;
VAL_ 656 iBCM_12VBattCpLowWarn 1 "Warning" 0 "No Warning" ;
VAL_ 656 iBCM_ForceIGN_ONReq 1 "Request" 0 "No Request" ;
VAL_ 656 iBCM_RemtKeyVldIndcn 1 "Validity" 0 "Invalidity" ;
VAL_ 400 iBCM_AntitheftSts 3 "Alarmed" 2 "Prearmed" 1 "Armed" 0 "Disarmed" ;
VAL_ 400 iBCM_PwrMod 3 "Reserved" 2 "ON" 1 "ACC" 0 "OFF" ;
VAL_ 400 iBCM_HoodSts 1 "Open" 0 "Close" ;
VAL_ 400 iBCM_VhclDoorLckSts 1 "Lock" 0 "Unlock" ;
VAL_ 400 iBCM_FL_DoorAjarSts 1 "Open" 0 "Close" ;
VAL_ 400 iBCM_FR_DoorAjarSts 1 "Open" 0 "Close" ;
VAL_ 400 iBCM_RL_DoorAjarSts 1 "Open" 0 "Close" ;
VAL_ 400 iBCM_RR_DoorAjarSts 1 "Open" 0 "Close" ;
VAL_ 400 iBCM_PBDLckSts 1 "Lock" 0 "Unlock" ;
VAL_ 400 iBCM_PosnLiSts 1 "On" 0 "Off" ;
VAL_ 400 iBCM_HiBeamSts 1 "On" 0 "Off" ;
VAL_ 400 iBCM_LoBeamSts 1 "On" 0 "Off" ;
VAL_ 400 iBCM_ReFogLiSts 1 "On" 0 "Off" ;
VAL_ 400 iBCM_FrntFogLiSts 1 "On" 0 "Off" ;
VAL_ 400 iBCM_TurnLiSts 3 "Hazard warning on" 2 "Left turn lamp on" 1 "Right turn lamp on" 0 "Off" ;
VAL_ 400 iBCM_BrkLiSwch 1 "On" 0 "Off" ;
VAL_ 400 iBCM_DrvrPresenceSgnl 3 "Reserved" 2 "Error" 1 "Have Person" 0 "No Person" ;
VAL_ 400 iBCM_FolwMeHomeSts 1 "On" 0 "Off/Default" ;
VAL_ 400 iBCM_HomeTiDlySetg 255 "Invalid" 254 "Invalid" 253 "Invalid" 252 "Invalid" 251 "Invalid" 250 "Invalid" 249 "Invalid" 248 "Invalid" 247 "Invalid" 246 "Invalid" 245 "Invalid" 244 "Invalid" 243 "Invalid" 242 "Invalid" 241 "Invalid" 240 "Invalid" 239 "Invalid" 238 "Invalid" 237 "Invalid" 236 "Invalid" 235 "Invalid" 234 "Invalid" 233 "Invalid" 232 "Invalid" 231 "Invalid" 230 "Invalid" 229 "Invalid" 228 "Invalid" 227 "Invalid" 226 "Invalid" 225 "Invalid" 224 "Invalid" 223 "Invalid" 222 "Invalid" 221 "Invalid" 220 "Invalid" 219 "Invalid" 218 "Invalid" 217 "Invalid" 216 "Invalid" 215 "Invalid" 214 "Invalid" 213 "Invalid" 212 "Invalid" 211 "Invalid" 210 "Invalid" 209 "Invalid" 208 "Invalid" 207 "Invalid" 206 "Invalid" 205 "Invalid" 204 "Invalid" 203 "Invalid" 202 "Invalid" 201 "Invalid" 200 "Invalid" 199 "Invalid" 198 "Invalid" 197 "Invalid" 196 "Invalid" 195 "Invalid" 194 "Invalid" 193 "Invalid" 192 "Invalid" 191 "Invalid" 190 "Invalid" 189 "Invalid" 188 "Invalid" 187 "Invalid" 186 "Invalid" 185 "Invalid" 184 "Invalid" 183 "Invalid" 182 "Invalid" 181 "Invalid" 180 "Invalid" 179 "Invalid" 178 "Invalid" 177 "Invalid" 176 "Invalid" 175 "Invalid" 174 "Invalid" 173 "Invalid" 172 "Invalid" 171 "Invalid" 170 "Invalid" 169 "Invalid" 168 "Invalid" 167 "Invalid" 166 "Invalid" 165 "Invalid" 164 "Invalid" 163 "Invalid" 162 "Invalid" 161 "Invalid" 160 "Invalid" 159 "Invalid" 158 "Invalid" 157 "Invalid" 156 "Invalid" 155 "Invalid" 154 "Invalid" 153 "Invalid" 152 "Invalid" 151 "Invalid" 150 "Invalid" 149 "Invalid" 148 "Invalid" 147 "Invalid" 146 "Invalid" 145 "Invalid" 144 "Invalid" 143 "Invalid" 142 "Invalid" 141 "Invalid" 140 "Invalid" 139 "Invalid" 138 "Invalid" 137 "Invalid" 136 "Invalid" 135 "Invalid" 134 "Invalid" 133 "Invalid" 132 "Invalid" 131 "Invalid" 130 "Invalid" 129 "Invalid" 128 "Invalid" 127 "Invalid" 126 "Invalid" 125 "Invalid" 124 "Invalid" 123 "Invalid" 122 "Invalid" 121 "Invalid" 120 "Invalid" 119 "Invalid" 118 "Invalid" 117 "Invalid" 116 "Invalid" 115 "Invalid" 114 "Invalid" 113 "Invalid" 112 "Invalid" 111 "Invalid" 110 "Invalid" 109 "Invalid" 108 "Invalid" 107 "Invalid" 106 "Invalid" 105 "Invalid" 104 "Invalid" 103 "Invalid" 102 "Invalid" 101 "Invalid" 100 "Invalid" 99 "Invalid" 98 "Invalid" 97 "Invalid" 96 "Invalid" 95 "Invalid" 94 "Invalid" 93 "Invalid" 92 "Invalid" 91 "Invalid" 90 "Invalid" 89 "Invalid" 88 "Invalid" 87 "Invalid" 86 "Invalid" 85 "Invalid" 84 "Invalid" 83 "Invalid" 82 "Invalid" 81 "Invalid" 80 "Invalid" 79 "Invalid" 78 "Invalid" 77 "Invalid" 76 "Invalid" 75 "Invalid" 74 "Invalid" 73 "Invalid" 72 "Invalid" 71 "Invalid" 70 "Invalid" 69 "Invalid" 68 "Invalid" 67 "Invalid" 66 "Invalid" 65 "Invalid" 64 "Invalid" 63 "Invalid" 62 "Invalid" 61 "Invalid" ;
